# M471 register map
File version: 1.0
Registers are 32-bit, read-write, reset 0x0 unless marked. A register's access mark holds for its fields unless they carry their own. Offsets are from the block's base; [hi:lo] are bit positions; {n}, {i} and the like mark numbered series; 'fields as' and 'values as' point back to an identical list.

## EPWM0 (part 2 of 2) — EPWM Register Map
Base 0x40058000
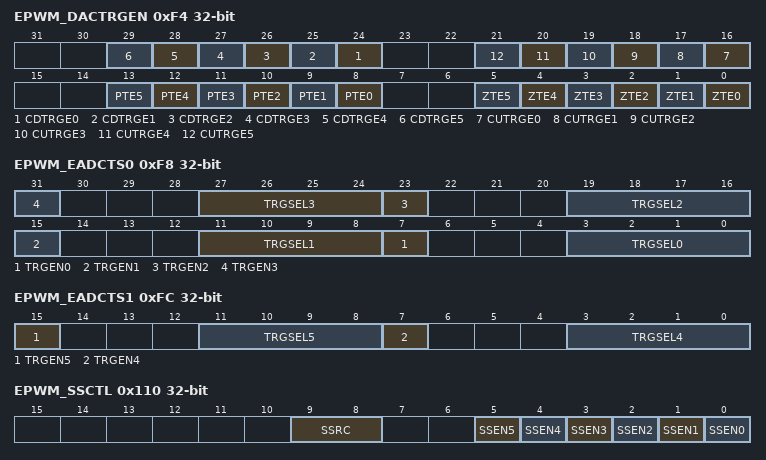
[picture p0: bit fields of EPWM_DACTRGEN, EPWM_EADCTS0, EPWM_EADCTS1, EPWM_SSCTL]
0xF4 EPWM_DACTRGEN — EPWM Trigger DAC Enable Register
  [n+24] CDTRGE{n} (n=0..5) — EPWM Compare Down Count Point Trigger DAC Enable Bits. EPWM can trigger DAC to start action when EPWM counter down count to CMP if this bit is set to1. Note 1: This bit should keep at 0 when EPWM counter operating in up counter type. Note 2: In complementary mode, CDTRGEN1, 3, 5 is used as another CDTRGEN for channel 0, 2, 4.
    0=EPWM Compare Down count point trigger DAC function Disabled; 1=EPWM Compare Down count point trigger DAC function Enabled
  [n+16] CUTRGE{n} (n=0..5) — EPWM Compare Up Count Point Trigger DAC Enable Bits. EPWM can trigger DAC to start action when EPWM counter counts up to CMP if this bit is set to1. Note 1: This bit should keep at 0 when EPWM counter operating in down counter type. Note 2: In complementary mode, CUTRGEN1, 3, 5 is used as another CUTRGEN for channel 0, 2, 4.
    0=EPWM Compare Up point trigger DAC function Disabled; 1=EPWM Compare Up point trigger DAC function Enabled
  [n+8] PTE{n} (n=0..5) — EPWM Period Point Trigger DAC Enable Bits. EPWM can trigger DAC to start action when EPWM counter counts up to (PERIODn+1) if this bit is set to1.
    0=EPWM period point trigger DAC function Disabled; 1=EPWM period point trigger DAC function Enabled
  [n] ZTE{n} (n=0..5) — EPWM Zero Point Trigger DAC Enable Bits. EPWM can trigger EADC/DAC/DMA to start action when EPWM counter down count to zero if this bit is set to1.
    values as PTE0
0xF8 EPWM_EADCTS0 — EPWM Trigger EADC Source Select Register 0
  [8n+7] TRGEN{n} (n=0..3) — EPWM_CH{n} Trigger EADC Enable Bit
    0=EPWM_CH{n} Trigger EADC function Disabled; 1=EPWM_CH{n} Trigger EADC function Enabled
  [27:24] TRGSEL3 — EPWM_CH3 Trigger EADC Source Select
    0=EPWM_CH2 zero point; 1=EPWM_CH2 period point; 2=EPWM_CH2 zero or period point; 3=EPWM_CH2 up-count compared point; 4=EPWM_CH2 down-count compared point; 5=EPWM_CH3 zero point; 6=EPWM_CH3 period point; 7=EPWM_CH3 zero or period point; 8=EPWM_CH3 up-count compared point; 9=EPWM_CH3 down-count compared point; 10=EPWM_CH0 up-count free trigger compared point; 11=EPWM_CH0 down-count free trigger compared point; 12=EPWM_CH2 up-count free trigger compared point; 13=EPWM_CH2 down-count free trigger compared point; 14=EPWM_CH4 up-count free trigger compared point; 15=EPWM_CH4 down-count free trigger compared point
  [19:16] TRGSEL2 — EPWM_CH2 Trigger EADC Source Select
    values as TRGSEL3
  [11:8] TRGSEL1 — EPWM_CH1 Trigger EADC Source Select
    0=EPWM_CH0 zero point; 1=EPWM_CH0 period point; 2=EPWM_CH0 zero or period point; 3=EPWM_CH0 up-count compared point; 4=EPWM_CH0 down-count compared point; 5=EPWM_CH1 zero point; 6=EPWM_CH1 period point; 7=EPWM_CH1 zero or period point; 8=EPWM_CH1 up-count compared point; 9=EPWM_CH1 down-count compared point; 10=EPWM_CH0 up-count free trigger compared point; 11=EPWM_CH0 down-count free trigger compared point; 12=EPWM_CH2 up-count free trigger compared point; 13=EPWM_CH2 down-count free trigger compared point; 14=EPWM_CH4 up-count free trigger compared point; 15=EPWM_CH4 down-count free trigger compared point
  [3:0] TRGSEL0 — EPWM_CH0 Trigger EADC Source Select
    values as TRGSEL1
0xFC EPWM_EADCTS1 — EPWM Trigger EADC Source Select Register 1
  [15] TRGEN5 — EPWM_CH5 Trigger EADC Enable Bit
    0=EPWM_CH5 Trigger EADC function Disabled; 1=EPWM_CH5 Trigger EADC function Enabled
  [11:8] TRGSEL5 — EPWM_CH5 Trigger EADC Source Select
    0=EPWM_CH4 zero point; 1=EPWM_CH4 period point; 2=EPWM_CH4 zero or period point; 3=EPWM_CH4 up-count compared point; 4=EPWM_CH4 down-count compared point; 5=EPWM_CH5 zero point; 6=EPWM_CH5 period point; 7=EPWM_CH5 zero or period point; 8=EPWM_CH5 up-count compared point; 9=EPWM_CH5 down-count compared point; 10=EPWM_CH0 up-count free trigger compared point; 11=EPWM_CH0 down-count free trigger compared point; 12=EPWM_CH2 up-count free trigger compared point; 13=EPWM_CH2 down-count free trigger compared point; 14=EPWM_CH4 up-count free trigger compared point; 15=EPWM_CH4 down-count free trigger compared point
  [7] TRGEN4 — EPWM_CH4 Trigger EADC Enable Bit
    0=EPWM_CH4 Trigger EADC function Disabled; 1=EPWM_CH4 Trigger EADC function Enabled
  [3:0] TRGSEL4 — EPWM_CH4 Trigger EADC Source Select
    values as TRGSEL5
0x100 EPWM_FTCMPDAT0_1 — EPWM Free Trigger Compare Register 0/1
  [15:0] FTCMP — EPWM Free Trigger Compare Register
0x104 EPWM_FTCMPDAT2_3 — EPWM Free Trigger Compare Register 2/3
  [15:0] FTCMP — EPWM Free Trigger Compare Register
0x108 EPWM_FTCMPDAT4_5 — EPWM Free Trigger Compare Register 4/5
  [15:0] FTCMP — EPWM Free Trigger Compare Register
0x110 EPWM_SSCTL — EPWM Synchronous Start Control Register
  [9:8] SSRC — EPWM Synchronous Start Source Select Bits
    0=Synchronous start source come from EPWM0; 1=Synchronous start source come from EPWM1; 2=Synchronous start source come from BPWM0; 3=Synchronous start source come from BPWM1
  [n] SSEN{n} (n=0..5) — EPWM Synchronous Start Function Enable Bits. When synchronous start function is enabled, the EPWM counter enable register (EPWM_CNTEN) can be enabled by writing EPWM synchronous start trigger bit (CNTSEN).
    0=EPWM synchronous start function Disabled; 1=EPWM synchronous start function Enabled
0x114 EPWM_SSTRG wo — EPWM Synchronous Start Trigger Register
  [0] CNTSEN — EPWM Counter Synchronous Start Enable (Write Only). PMW counter synchronous enable function is used to make selected EPWM channels (include EPWM0_CHx and EPWM1_CHx) start counting at the same time. Writing this bit to 1 will also set the counter enable bit (CNTENn, n denotes channel 0 to 5) if correlated EPWM channel counter synchronous start function is enabled.
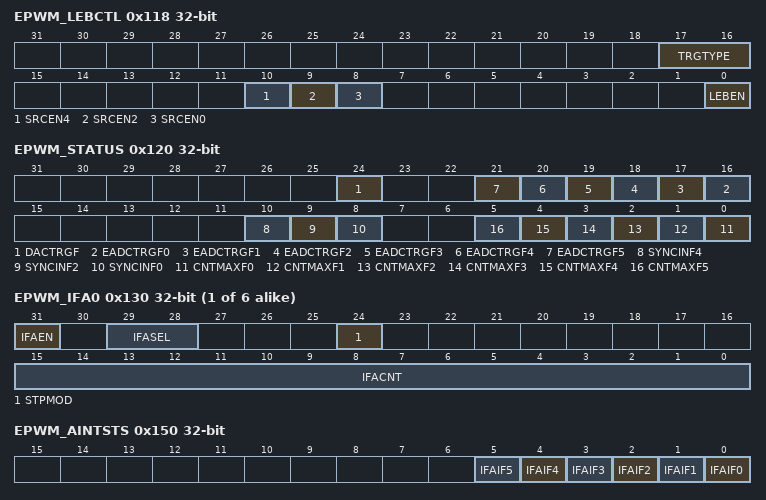
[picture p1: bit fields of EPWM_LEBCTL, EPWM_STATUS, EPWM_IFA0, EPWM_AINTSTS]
0x118 EPWM_LEBCTL — EPWM Leading Edge Blanking Control Register
  [17:16] TRGTYPE — EPWM Leading Edge Blanking Trigger Type
    0=When detect leading edge blanking source rising edge, blanking counter start counting; 1=When detect leading edge blanking source falling edge, blanking counter start counting; 2=When detect leading edge blanking source rising or falling edge, blanking counter start counting
  [10] SRCEN4 — EPWM Leading Edge Blanking Source From EPWM_CH4 Enable Bit
    0=EPWM Leading Edge Blanking Source from EPWM_CH4 Disabled; 1=EPWM Leading Edge Blanking Source from EPWM_CH4 Enabled
  [9] SRCEN2 — EPWM Leading Edge Blanking Source From EPWM_CH2 Enable Bit
    0=EPWM Leading Edge Blanking Source from EPWM_CH2 Disabled; 1=EPWM Leading Edge Blanking Source from EPWM_CH2 Enabled
  [8] SRCEN0 — EPWM Leading Edge Blanking Source From EPWM_CH0 Enable Bit
    0=EPWM Leading Edge Blanking Source from EPWM_CH0 Disabled; 1=EPWM Leading Edge Blanking Source from EPWM_CH0 Enabled
  [0] LEBEN — EPWM Leading Edge Blanking Enable Bit
    0=EPWM Leading Edge Blanking Disabled; 1=EPWM Leading Edge Blanking Enabled
0x11C EPWM_LEBCNT — EPWM Leading Edge Blanking Counter Register
  [8:0] LEBCNT — EPWM Leading Edge Blanking Counter
0x120 EPWM_STATUS
  [24] DACTRGF — DAC Start of Conversion Flag. Note: This bit can be cleared by software writing 1.
    0=No DAC start of conversion trigger event has occurred; 1=A DAC start of conversion trigger event has occurred
  [n+16] EADCTRGF{n} (n=0..5) — EADC Start of Conversion Flag. Note: This bit can be cleared by software writing 1.
    0=No EADC start of conversion trigger event has occurred; 1=An EADC start of conversion trigger event has occurred
  [10] SYNCINF4 — Input Synchronization Latched Flag. Note: This bit can be cleared by software writing 1.
    0=No SYNC_IN event has occurred; 1=A SYNC_IN event has occurred
  [9] SYNCINF2 — Input Synchronization Latched Flag. Note: This bit can be cleared by software writing 1.
    values as SYNCINF4
  [8] SYNCINF0 — Input Synchronization Latched Flag. Note: This bit can be cleared by software writing 1.
    values as SYNCINF4
  [n] CNTMAXF{n} (n=0..5) — Time-base Counter Equal to 0xFFFF Latched Flag. Note: This bit can be cleared by software writing 1.
    0=The time-base counter never reached its maximum value 0xFFFF; 1=The time-base counter reached its maximum value
{0x130+4i} EPWM_IFA{i} (i=0..5) — EPWM Interrupt Flag Accumulator Register {i}
  [31] IFAEN — EPWM_CHn Interrupt Flag Accumulator Enable Bit. Note: Disabling this bit will reset related EPWM_IFACNT
    0=EPWM_CHn interrupt flag accumulator Disabled; 1=EPWM_CHn interrupt flag accumulator Enabled
  [29:28] IFASEL — EPWM_CHn Interrupt Flag Accumulator Source Select
    0=EPWM_CHn zero point; 1=EPWM_CHn period in channel n; 2=EPWM_CHn up-count compared point; 3=EPWM_CHn down-count compared point
  [24] STPMOD — EPWM_CHn Accumulator Stop Mode Enable Bit
    0=EPWM_CHn Stop Mode Disabled; 1=EPWM_CHn Stop Mode Enabled
  [15:0] IFACNT — EPWM_CHn Interrupt Flag Counter. The register sets the count number which defines (IFACNT+1) times of EPWM_CHn period occurs to set bit IFAIFn to request the EPWM period interrupt.EPWM flag will be set in every IFACNT[15:0] times of EPWM period.
0x150 EPWM_AINTSTS — EPWM Accumulator Interrupt Flag Register
  [n] IFAIF{n} (n=0..5) — EPWM_CHn Interrupt Flag Accumulator Interrupt Flag. Flag is set by hardware when condition match IFASEL in EPWM_IFAn register, software can clear this bit by writing 1 to it.
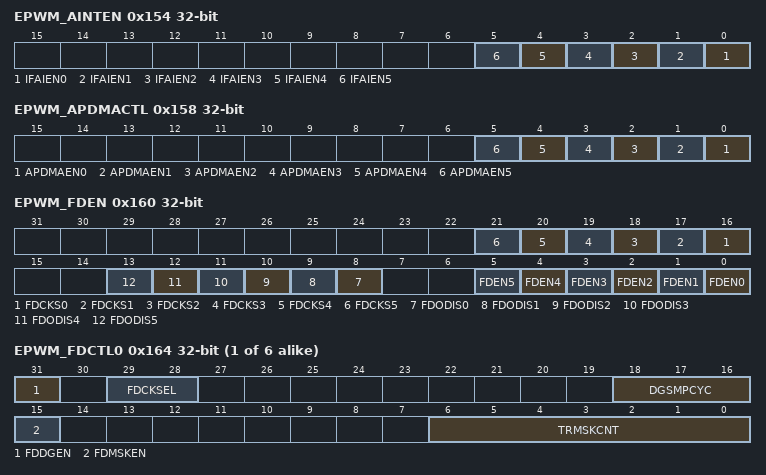
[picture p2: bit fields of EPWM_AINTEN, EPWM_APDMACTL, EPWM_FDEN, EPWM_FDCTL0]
0x154 EPWM_AINTEN — EPWM Accumulator Interrupt Enable Register
  [all] fields
    0=Interrupt Flag accumulator interrupt Disabled; 1=Interrupt Flag accumulator interrupt Enabled
  [n] IFAIEN{n} (n=0..5) — EPWM_CHn Interrupt Flag Accumulator Interrupt Enable Bits
0x158 EPWM_APDMACTL — EPWM Accumulator PDMA Control Register
  [all] fields
    0=Channel n PDMA function Disabled; 1=Channel n PDMA function Enabled for the channel n to trigger PDMA to transfer memory data to register
  [n] APDMAEN{n} (n=0..5) — Channel n Accumulator PDMA Enable Bits
0x160 EPWM_FDEN — EPWM Fault Detect Enable Register
  [n+16] FDCKS{n} (n=0..5) — EPWM Channel n Fault Detect Clock Source Select Bits
    0=EPWMx_CLK, x denotes 0 or 1; 1=EPWMx_CLK divide by prescaler, x denotes 0 or 1
  [n+8] FDODIS{n} (n=0..5) — EPWM Channel n Output Fault Detect Disable Bits
    0=EPWM detect fault and output Enabled; 1=EPWM detect fault and output Disabled
  [n] FDEN{n} (n=0..5) — EPWM Fault Detect Function Enable Bits
    0=Fault detect function Disabled; 1=Fault detect function Enabled
{0x164+4i} EPWM_FDCTL{i} (i=0..5) — EPWM Fault Detect Control Register {i}
  [31] FDDGEN — Fault Detect Deglitch Enable Bit
    0=Fault detect deglitch function Disabled; 1=Fault detect deglitch function Enabled
  [29:28] FDCKSEL — EPWM Channel Fault Detect Clock Select
    0=FLT_CLK/1; 1=FLT_CLK/2; 2=FLT_CLK/4; 3=FLT_CLK/8
  [18:16] DGSMPCYC — Deglitch Sampling Cycle. FDCKS is set to 0: Sampling detect signal each EPWMx_CLK * (2^FDCKSEL) period and detect DGSMPCYC+1 times. FDCKS is set to 1: Sampling detect signal each EPWMx_CLK * CLKPSC * (2^FDCKSEL) period and detect DGSMPCYC+1 times . Note: CLKPSC (EPWM_CLKPSCn[11:0]) is 0:
  [15] FDMSKEN — Fault Detect Mask Enable Bit
    0=Fault detect mask function Disabled; 1=Fault detect mask function Enabled
  [6:0] TRMSKCNT — Transition Mask Counter. The fault detect result will be masked before counter count from 0 to TRMSKCNT. . FDCKS is set to 0: Mask time is EPWMx_CLK * (2^FDCKSEL) * (TRMSKCNT+2). FDCKS is set to 1: Mask time EPWMx_CLK * CLKPSC * (2^FDCKSEL) * (TRMSKCNT+2) . Note: CLKPSC (EPWM_CLKPSCn[11:0]) is 0:
0x17C EPWM_FDIEN — EPWM Fault Detect Interrupt Enable Register
  [0] FDIENn — EPWM Channel n Fault Detect Interrupt Enable Bit
    0=EPWM Channel n Fault Detect Interrupt Disabled; 1=EPWM Channel n Fault Detect Interrupt Enabled
0x180 EPWM_FDSTS — EPWM Fault Detect Interrupt Flag Register
  [5:0] FDIFn — EPWM Channel n Fault Detect Interrupt Flag Bit. Fault Detect Interrupt Flag will be set when EPWM output short. Software can clear this bit by writing 1 to it.
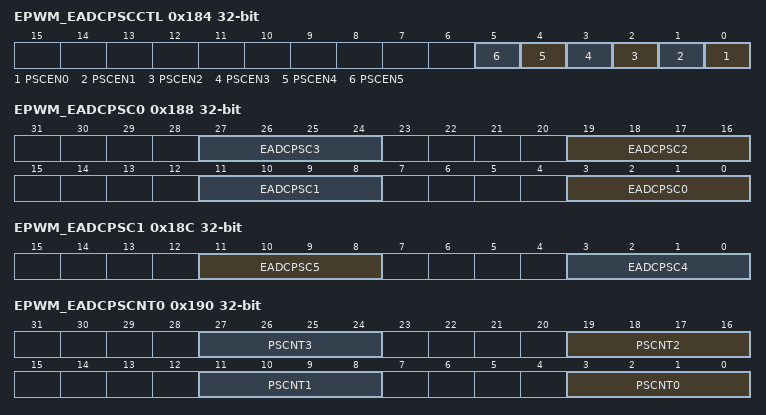
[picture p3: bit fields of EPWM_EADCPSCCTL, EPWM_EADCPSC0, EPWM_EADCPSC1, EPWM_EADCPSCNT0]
0x184 EPWM_EADCPSCCTL — EPWM Trigger EADC Prescale Control Register
  [all] fields
    0=EPWM Trigger EADC Pre-scale function Disabled; 1=EPWM Trigger EADC Pre-scale function Enabled
  [n] PSCEN{n} (n=0..5) — EPWM Trigger EADC Pre-scale Function Enable Bits
0x188 EPWM_EADCPSC0 — EPWM Trigger EADC Prescale Register 0
  [8n+3:8n] EADCPSC{n} (n=0..3) — EPWM Channel {n} Trigger EADC Prescale. The register sets the count number which defines (EADCPSC{n}+1) times of EPWM_CH{n} trigger EADC event occurs to trigger EADC and set trigger EADC flag bit EADCTRGF{n}.
0x18C EPWM_EADCPSC1 — EPWM Trigger EADC Prescale Register 1
  [11:8] EADCPSC5 — EPWM Channel 5 Trigger EADC Prescale. The register sets the count number which defines (EADCPSC5+1) times of EPWM_CH5 trigger EADC event occurs to trigger EADC and set trigger EADC flag bit EADCTRGF5.
  [3:0] EADCPSC4 — EPWM Channel 4 Trigger EADC Prescale. The register sets the count number which defines (EADCPSC4+1) times of EPWM_CH4 trigger EADC event occurs to trigger EADC and set trigger EADC flag bit EADCTRGF4.
0x190 EPWM_EADCPSCNT0 — EPWM Trigger EADC Prescale Counter Register 0
  [8n+3:8n] PSCNT{n} (n=0..3) — EPWM Trigger EADC Prescale Counter {n}. User can monitor PSCNT{n} to know the current value in 4-bit trigger EADC prescale counter. Note 1: user can write only when PSCEN{n} is 0. Note 2: Write data limitation: PSCNT{n} EADCPSC{n}.
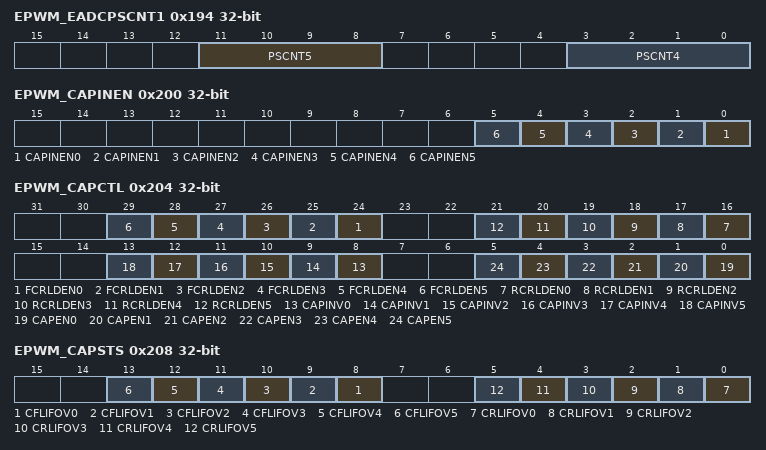
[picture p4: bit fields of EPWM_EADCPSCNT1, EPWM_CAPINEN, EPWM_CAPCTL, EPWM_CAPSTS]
0x194 EPWM_EADCPSCNT1 — EPWM Trigger EADC Prescale Counter Register 1
  [11:8] PSCNT5 — EPWM Trigger EADC Prescale Counter 5. User can monitor PSCNT5 to know the current value in 4-bit trigger EADC prescale counter. Note 1: user can write only when PSCEN5 is 0. Note 2: Write data limitation: PSCNT5 EADCPSC5.
  [3:0] PSCNT4 — EPWM Trigger EADC Prescale Counter 4. User can monitor PSCNT4 to know the current value in 4-bit trigger EADC prescale counter. Note 1: user can write only when PSCEN4 is 0. Note 2: Write data limitation: PSCNT4 EADCPSC4.
0x200 EPWM_CAPINEN — EPWM Capture Input Enable Register
  [all] fields
    0=EPWM Channel capture input path Disabled. The input of EPWM channel capture function is always regarded as 0; 1=EPWM Channel capture input path Enabled. The input of EPWM channel capture function comes from correlative multifunction pin
  [n] CAPINEN{n} (n=0..5) — Capture Input Enable Bits
0x204 EPWM_CAPCTL — EPWM Capture Control Register
  [n+24] FCRLDEN{n} (n=0..5) — Falling Capture Reload Enable Bits
    0=Falling capture reload counter Disabled; 1=Falling capture reload counter Enabled
  [n+16] RCRLDEN{n} (n=0..5) — Rising Capture Reload Enable Bits
    0=Rising capture reload counter Disabled; 1=Rising capture reload counter Enabled
  [n+8] CAPINV{n} (n=0..5) — Capture Inverter Enable Bits
    0=Capture source inverter Disabled; 1=Capture source inverter Enabled. Reverse the input signal from GPIO
  [n] CAPEN{n} (n=0..5) — Capture Function Enable Bits
    0=Capture function Disabled. EPWM_RCAPDATn/EPWM_FCAPDATn register will not be updated; 1=Capture function Enabled. Capture latched the EPWM counter value when detected rising or falling edge of input signal and saved to RCAPDAT (Rising latch) and FCAPDAT (Falling latch)
0x208 EPWM_CAPSTS ro — EPWM Capture Status Register
  [n+8] CFLIFOV{n} (n=0..5) — Capture Falling Latch Interrupt Flag Overrun Status (Read Only). This flag indicates if falling latch happened when the corresponding CFLIFn(EPWM_CAPIF[8+n]) is 1. Note: This bit will be cleared automatically when user clear corresponding CFLIFn(EPWM_CAPIF[8+n]).
  [n] CRLIFOV{n} (n=0..5) — Capture Rising Latch Interrupt Flag Overrun Status (Read Only). This flag indicates if rising latch happened when the corresponding CRLIFn(EPWM_CAPIF[n]) is 1. Note: This bit will be cleared automatically when user clear corresponding CRLIFn(EPWM_CAPIF[n]).
{0x20C+8i} EPWM_RCAPDAT{i} ro (i=0..5) — EPWM Rising Capture Data Register {i}
  [15:0] RCAPDAT — EPWM Rising Capture Data Register (Read Only). When rising capture condition happened, the EPWM counter value will be saved in this register.
{0x210+8i} EPWM_FCAPDAT{i} ro (i=0..5) — EPWM Falling Capture Data Register {i}
  [15:0] FCAPDAT — EPWM Falling Capture Data Register (Read Only). When falling capture condition happened, the EPWM counter value will be saved in this register.
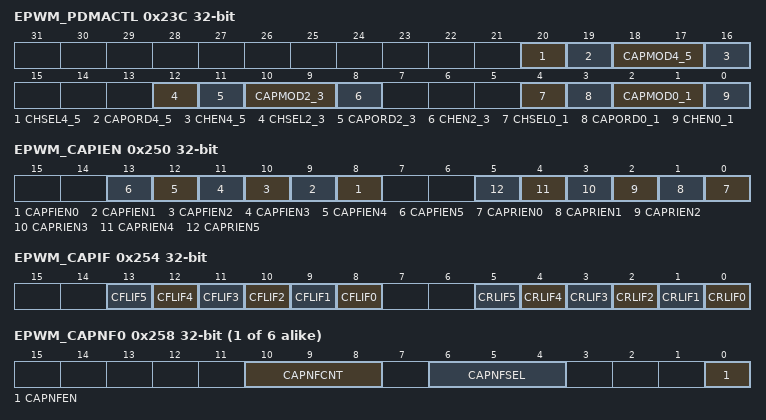
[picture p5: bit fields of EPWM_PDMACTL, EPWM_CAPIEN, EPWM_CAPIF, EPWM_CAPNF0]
0x23C EPWM_PDMACTL — EPWM PDMA Control Register
  [20] CHSEL4_5 — Select Channel 4/5 to Do PDMA Transfer
    0=Channel4; 1=Channel5
  [19] CAPORD4_5 — Capture Channel 4/5 Rising/Falling Order
    0=EPWM_FCAPDAT4/5 is the first captured data to memory; 1=EPWM_RCAPDAT4/5 is the first captured data to memory
  [18:17] CAPMOD4_5 — Select EPWM_RCAPDAT4/5 or EPWM_FCAPDAT4/5 to Do PDMA Transfer
    1=EPWM_RCAPDAT4/5; 2=EPWM_FCAPDAT4/5; 3=Both EPWM_RCAPDAT4/5 and EPWM_FCAPDAT4/5
  [16] CHEN4_5 — Channel 4/5 PDMA Enable Bit
    0=Channel 4/5 PDMA function Disabled; 1=Channel 4/5 PDMA function Enabled for the channel 4/5 captured data and transfer to memory
  [12] CHSEL2_3 — Select Channel 2/3 to Do PDMA Transfer
    0=Channel2; 1=Channel3
  [11] CAPORD2_3 — Capture Channel 2/3 Rising/Falling Order
    0=EPWM_FCAPDAT2/3 is the first captured data to memory; 1=EPWM_RCAPDAT2/3 is the first captured data to memory
  [10:9] CAPMOD2_3 — Select EPWM_RCAPDAT2/3 or EPWM_FCAODAT2/3 to Do PDMA Transfer
    1=EPWM_RCAPDAT2/3; 2=EPWM_FCAPDAT2/3; 3=Both EPWM_RCAPDAT2/3 and EPWM_FCAPDAT2/3
  [8] CHEN2_3 — Channel 2/3 PDMA Enable Bit
    0=Channel 2/3 PDMA function Disabled; 1=Channel 2/3 PDMA function Enabled for the channel 2/3 captured data and transfer to memory
  [4] CHSEL0_1 — Select Channel 0/1 to Do PDMA Transfer
    0=Channel0; 1=Channel1
  [3] CAPORD0_1 — Capture Channel 0/1 Rising/Falling Order
    0=EPWM_FCAPDAT0/1 is the first captured data to memory; 1=EPWM_RCAPDAT0/1 is the first captured data to memory
  [2:1] CAPMOD0_1 — Select EPWM_RCAPDAT0/1 or EPWM_FCAPDAT0/1 to Do PDMA Transfer
    1=EPWM_RCAPDAT0/1; 2=EPWM_FCAPDAT0/1; 3=Both EPWM_RCAPDAT0/1 and EPWM_FCAPDAT0/1
  [0] CHEN0_1 — Channel 0/1 PDMA Enable Bit
    0=Channel 0/1 PDMA function Disabled; 1=Channel 0/1 PDMA function Enabled for the channel 0/1 captured data and transfer to memory
0x240 EPWM_PDMACAP0_1 ro — EPWM Capture Channel 01 PDMA Register
  [15:0] CAPBUF — EPWM Capture PDMA Register (Read Only). This register is used as a buffer to transfer EPWM capture rising or falling data to memory by PDMA.
0x244 EPWM_PDMACAP2_3 ro — EPWM Capture Channel 23 PDMA Register
  fields as EPWM_PDMACAP0_1
0x248 EPWM_PDMACAP4_5 ro — EPWM Capture Channel 45 PDMA Register
  fields as EPWM_PDMACAP0_1
0x250 EPWM_CAPIEN — EPWM Capture Interrupt Enable Register
  [n+8] CAPFIEN{n} (n=0..5) — EPWM Capture Falling Latch Interrupt Enable Bits
    0=Capture falling edge latch interrupt Disabled; 1=Capture falling edge latch interrupt Enabled
  [n] CAPRIEN{n} (n=0..5) — EPWM Capture Rising Latch Interrupt Enable Bits
    0=Capture rising edge latch interrupt Disabled; 1=Capture rising edge latch interrupt Enabled
0x254 EPWM_CAPIF — EPWM Capture Interrupt Flag Register
  [n+8] CFLIF{n} (n=0..5) — EPWM Capture Falling Latch Interrupt Flag. Note 1: When Capture with PDMA operating, EPWM_CAPIF corresponding channel CFLIFn will be cleared by hardware after PDMA transfer data. Note 2: This bit is cleared by writing 1 to it.
    0=No capture falling latch condition happened; 1=Capture falling latch condition happened, this flag will be set to high
  [n] CRLIF{n} (n=0..5) — EPWM Capture Rising Latch Interrupt Flag. Note 1: When Capture with PDMA operating, EPWM_CAPIF corresponding channel CRLIFn will be cleared by hardware after PDMA transfer data. Note 2: This bit is cleared by writing 1 to it.
    0=No capture rising latch condition happened; 1=Capture rising latch condition happened, this flag will be set to high
{0x258+4i} EPWM_CAPNF{i} (i=0..5) — EPWM Capture Input Noise Filter Register {i}
  [10:8] CAPNFCNT — Capture Edge Detector Noise Filter Count. The register bits control the capture filter counter to count from 0 to CAPNFCNT.
  [6:4] CAPNFSEL — Capture Edge Detector Noise Filter Clock Selection
    0=Filter clock = PCLK; 1=Filter clock = PCLK/2; 2=Filter clock = PCLK/4; 3=Filter clock = PCLK/8; 4=Filter clock = PCLK/16; 5=Filter clock = PCLK/32; 6=Filter clock = PCLK/64; 7=Filter clock = PCLK/128
  [0] CAPNFEN — Capture Noise Filter Enable
    0=Capture Noise Filter function Disabled; 1=Capture Noise Filter function Enabled
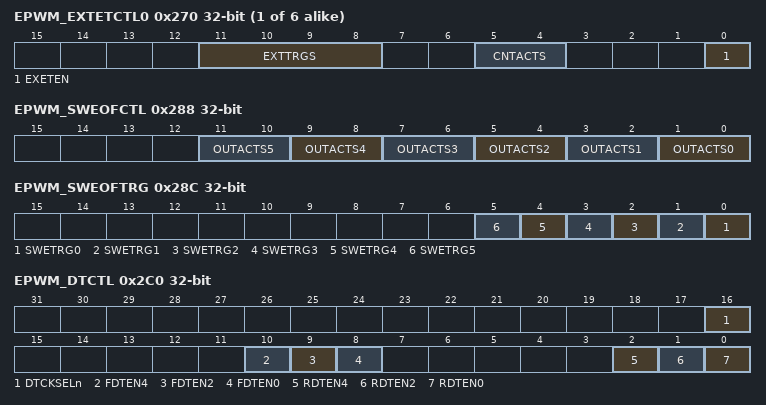
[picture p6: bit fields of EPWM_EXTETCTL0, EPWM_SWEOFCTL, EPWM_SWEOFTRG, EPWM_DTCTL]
{0x270+4i} EPWM_EXTETCTL{i} (i=0..5) — EPWM External Event Trigger Control Register {i}
  [11:8] EXTTRGS — External Trigger Selection
    {v}=INT{v} (v=0..7)
  [5:4] CNTACTS — Counter Action Selection
    0=Counter reset; 1=Counter start; 2=Counter reset and start; 3=Reseved
  [0] EXETEN — External Event Trigger Enable Bit
    0=External Event Trigger function Disabled; 1=External Event Trigger function Enabled
0x288 EPWM_SWEOFCTL — EPWM Software Event Output Force Control Register
  [all] fields
    0=Do nothing; 1=EPWM output Low; 2=EPWM output High; 3=EPWM output Toggle
  [2n+1:2n] OUTACTS{n} (n=0..5) — Output Action Selection
0x28C EPWM_SWEOFTRG — EPWM Software Event Output Force Trigger Register
  [n] SWETRG{n} (n=0..5) — Software Event Trigger. Write 1 to this bit will change EPWM output status according to OUTACTSn in EPWMx_SWEOFCTL setting. Note: This bit will auto cleared by hardware.
{0x290+4i} EPWM_CLKPSC{i} (i=0..5) — EPWM Clock Prescale Register {i}
  [11:0] CLKPSC — EPWM Counter Clock Prescale. The clock of EPWM counter is decided by clock prescaler. Each EPWM pair share one EPWM counter clock prescaler. The clock of EPWM counter is divided by (CLKPSC+ 1).
0x2A8 EPWM_RDTCNT0_1 — EPWM Rising Dead-time Counter Register 0/1
  [11:0] RDTCNT — Rising Dead-time Counter (Write Protect). The Rising dead-time can be calculated from the following formula: Note: This bit is write protected. Refer to SYS_REGLCTL register.
0x2AC EPWM_RDTCNT2_3 — EPWM Rising Dead-time Counter Register 2/3
  fields as EPWM_RDTCNT0_1
0x2B0 EPWM_RDTCNT4_5 — EPWM Rising Dead-time Counter Register 4/5
  fields as EPWM_RDTCNT0_1
0x2B4 EPWM_FDTCNT0_1 — EPWM Falling Dead-time Counter Register 0/1
  [11:0] FDTCNT — Falling Dead-time Counter (Write Protect). The dead-time can be calculated from the following formula: Note: This bit is write protected. Refer to SYS_REGLCTL register.
0x2B8 EPWM_FDTCNT2_3 — EPWM Falling Dead-time Counter Register 2/3
  fields as EPWM_FDTCNT0_1
0x2BC EPWM_FDTCNT4_5 — EPWM Falling Dead-time Counter Register 4/5
  fields as EPWM_FDTCNT0_1
0x2C0 EPWM_DTCTL — EPWM Dead-time Control Register
  [16] DTCKSELn — Dead-time Clock Select for EPWM Pair (EPWM_CH(n/2), EPWM_CH(n/2+1)) (Write Protect). Note: This bit is write protected. Refer to REGWRPROT register.
    0=Dead-time clock source from EPWM_CLK; 1=Dead-time clock source from prescaler output
  [10] FDTEN4 — Enable Falling Dead-time Insertion for EPWM Pair (EPWM_CH(n/2), EPWM_CH(n/2+1)) (Write Protect). Falling Dead-time insertion is only active when this pair of complementary EPWM is enabled. If falling dead- time insertion is inactive, the outputs of pin pair are complementary without any delay. Note: This bit is write protected. Refer to SYS_REGLCTL register.
    0=Falling Dead-time insertion Disabled on the pin pair; 1=Falling Dead-time insertion Enabled on the pin pair
  [9] FDTEN2 — Enable Falling Dead-time Insertion for EPWM Pair (EPWM_CH(n/2), EPWM_CH(n/2+1)) (Write Protect). Falling Dead-time insertion is only active when this pair of complementary EPWM is enabled. If falling dead- time insertion is inactive, the outputs of pin pair are complementary without any delay. Note: This bit is write protected. Refer to SYS_REGLCTL register.
    values as FDTEN4
  [8] FDTEN0 — Enable Falling Dead-time Insertion for EPWM Pair (EPWM_CH(n/2), EPWM_CH(n/2+1)) (Write Protect). Falling Dead-time insertion is only active when this pair of complementary EPWM is enabled. If falling dead- time insertion is inactive, the outputs of pin pair are complementary without any delay. Note: This bit is write protected. Refer to SYS_REGLCTL register.
    values as FDTEN4
  [2] RDTEN4 — Enable Rising Dead-time Insertion for EPWM Pair (EPWM_CH(n/2), EPWM_CH(n/2+1)) (Write Protect). Rising Dead-time insertion is only active when this pair of complementary EPWM is enabled. If rising dead- time insertion is inactive, the outputs of pin pair are complementary without any delay. Note: This bit is write protected. Refer to SYS_REGLCTL register.
    0=Rising Dead-time insertion Disabled on the pin pair; 1=Rising Dead-time insertion Enabled on the pin pair
  [1] RDTEN2 — Enable Rising Dead-time Insertion for EPWM Pair (EPWM_CH(n/2), EPWM_CH(n/2+1)) (Write Protect). Rising Dead-time insertion is only active when this pair of complementary EPWM is enabled. If rising dead- time insertion is inactive, the outputs of pin pair are complementary without any delay. Note: This bit is write protected. Refer to SYS_REGLCTL register.
    values as RDTEN4
  [0] RDTEN0 — Enable Rising Dead-time Insertion for EPWM Pair (EPWM_CH(n/2), EPWM_CH(n/2+1)) (Write Protect). Rising Dead-time insertion is only active when this pair of complementary EPWM is enabled. If rising dead- time insertion is inactive, the outputs of pin pair are complementary without any delay. Note: This bit is write protected. Refer to SYS_REGLCTL register.
    values as RDTEN4
{0x304+4i} EPWM_PBUF{i} ro (i=0..5) — EPWM PERIOD{i} Buffer
  [15:0] PBUF — EPWM Period Register Buffer (Read Only). Used as PERIOD active register.
{0x31C+4i} EPWM_CMPBUF{i} ro (i=0..5) — EPWM CMPDAT{i} Buffer
  [15:0] CMPBUF — EPWM Comparator Register Buffer (Read Only). Used as CMP active register.
0x334 EPWM_CPSCBUF0_1 ro — EPWM CLKPSC0_1 Buffer
  [11:0] CPSCBUF — EPWM Counter Clock Prescale Buffer. Used as EPWM counter clock pre-scale active register.
0x338 EPWM_CPSCBUF2_3 ro — EPWM CLKPSC2_3 Buffer
  fields as EPWM_CPSCBUF0_1
0x33C EPWM_CPSCBUF4_5 ro — EPWM CLKPSC4_5 Buffer
  fields as EPWM_CPSCBUF0_1
0x340 EPWM_FTCBUF0_1 ro — EPWM FTCMPDAT0_1 Buffer
  [15:0] FTCMPBUF — EPWM FTCMPDAT Buffer (Read Only). Used as FTCMP active buffer.
0x344 EPWM_FTCBUF2_3 ro — EPWM FTCMPDAT2_3 Buffer
  fields as EPWM_FTCBUF0_1
0x348 EPWM_FTCBUF4_5 ro — EPWM FTCMPDAT4_5 Buffer
  fields as EPWM_FTCBUF0_1
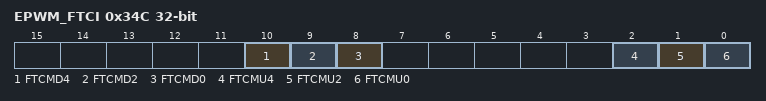
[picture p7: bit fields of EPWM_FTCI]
0x34C EPWM_FTCI — EPWM FTCMPDAT Indicator Register
  [10] FTCMD4 — EPWM FTCMPDAT Down Indicator. Indicator is set by hardware when EPWM counter down count and reaches EPWM_FTCMPDATn, software can clear this bit by writing 1 to it.
  [9] FTCMD2 — EPWM FTCMPDAT Down Indicator. Indicator is set by hardware when EPWM counter down count and reaches EPWM_FTCMPDATn, software can clear this bit by writing 1 to it.
  [8] FTCMD0 — EPWM FTCMPDAT Down Indicator. Indicator is set by hardware when EPWM counter down count and reaches EPWM_FTCMPDATn, software can clear this bit by writing 1 to it.
  [2] FTCMU4 — EPWM FTCMPDAT Up Indicator. Indicator is set by hardware when EPWM counter up count and reaches EPWM_FTCMPDATn, software can clear this bit by writing 1 to it.
  [1] FTCMU2 — EPWM FTCMPDAT Up Indicator. Indicator is set by hardware when EPWM counter up count and reaches EPWM_FTCMPDATn, software can clear this bit by writing 1 to it.
  [0] FTCMU0 — EPWM FTCMPDAT Up Indicator. Indicator is set by hardware when EPWM counter up count and reaches EPWM_FTCMPDATn, software can clear this bit by writing 1 to it.
{0x350+4i} EPWM_CPSCBUF{i} ro (i=0..5) — EPWM CLKPSC{i} Buffer
  fields as EPWM_CPSCBUF0_1
{0x368+4i} EPWM_IFACNT{i} ro (i=0..5) — EPWM Interrupt Flag Accumulator Counter {i}
  [15:0] ACUCNT — Accumulator Counter (Read Only). This value indicates how many interrupt are accumulated when using interrupt flag accumulator function.

## EPWM1 (part 2 of 2) — EPWM Register Map
Base 0x40059000
Registers as EPWM0; these are added or differ:
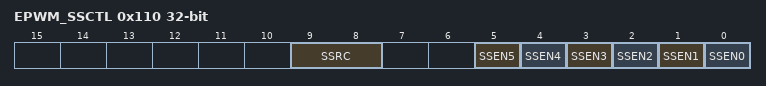
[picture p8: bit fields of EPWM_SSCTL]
0x110 EPWM_SSCTL — EPWM Synchronous Start Control Register
  fields as EPWM0.EPWM_SSCTL
0x114 EPWM_SSTRG wo — EPWM Synchronous Start Trigger Register
  fields as EPWM0.EPWM_SSTRG
